# AT32F402xx_v2 register map
Vendor: Keil; Series: AT32F402; File version: 1.0
CPU: CM4 r0p1, little endian, no MPU, FPU, 4 interrupt priority bits
Registers are 32-bit, read-write, reset 0x0 unless marked. A register's access mark holds for its fields unless they carry their own. Offsets are from the block's base; [hi:lo] are bit positions; 'fields as' and 'values as' point back to an identical list.

## FLASH — Flash memory controler
Base 0x40023C00
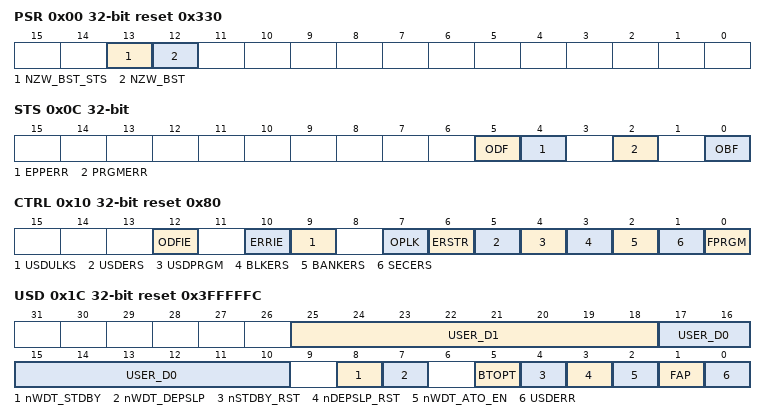
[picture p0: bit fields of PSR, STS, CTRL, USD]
0x00 PSR reset 0x330 — Performance selection register
  [13] NZW_BST_STS ro — Flash non-zero wait area boost status
  [12] NZW_BST — Flash non-zero wait area boost
0x04 UNLOCK wo
  [31:0] UKVAL — Unlock key value
0x08 USD_UNLOCK wo
  [31:0] USD_UKVAL — User system data Unlock key value
0x0C STS — Status register
  [5] ODF — Operate done flag
  [4] EPPERR — Erase/program protection error
  [2] PRGMERR — program error
  [0] OBF ro — Operate busy flag
0x10 CTRL reset 0x80 — Control register
  [12] ODFIE — Operation done flag interrupt enable
  [10] ERRIE — Error interrupt enable
  [9] USDULKS — User system data unlock success
  [7] OPLK — Operation lock
  [6] ERSTR — Erasing start
  [5] USDERS — User system data erase
  [4] USDPRGM — User system data program
  [3] BLKERS — Block erase
  [2] BANKERS — Bank erase
  [1] SECERS — Sector erase
  [0] FPRGM — Flash program
0x14 ADDR wo — Address register
  [31:0] FA — Flash Address
0x1C USD ro reset 0x3FFFFFC — User system data register
  [25:18] USER_D1 — User data 1
  [17:10] USER_D0 — User data 0
  [8] nWDT_STDBY — WDT standby
  [7] nWDT_DEPSLP — WDT deep sleep
  [5] BTOPT — boot option
  [4] nSTDBY_RST — Standby reset
  [3] nDEPSLP_RST — Deepsleep reset
  [2] nWDT_ATO_EN — WDT auto enable
  [1] FAP — FLASH access protection
  [0] USDERR — User system data error
0x20 EPPS0 ro reset 0xFFFFFFFF — Erase/program protection status register 0
  [31:0] EPPS — Erase/program protection status
0x2C EPPS1 ro reset 0xFFFFFFFF — Erase/program protection status register 1
  [31:0] EPPS — Erase/program protection status
0x44 UNLOCK2 wo
  [31:0] UKVAL — Unlock key value
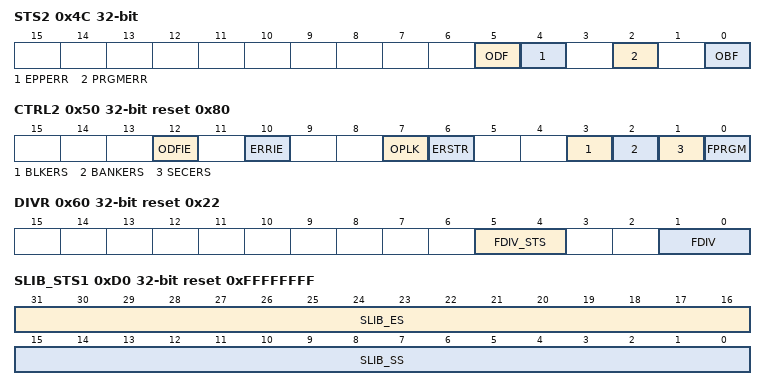
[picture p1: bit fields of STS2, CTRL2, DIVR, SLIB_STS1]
0x4C STS2 — Status 2 register
  fields as STS
0x50 CTRL2 reset 0x80 — Control 2 register
  [12] ODFIE — Operation done flag interrupt enable
  [10] ERRIE — Error interrupt enable
  [7] OPLK — Operation lock
  [6] ERSTR — Erasing start
  [3] BLKERS — Block erase
  [2] BANKERS — Bank erase
  [1] SECERS — Sector erase
  [0] FPRGM — Flash program
0x54 ADDR2 wo — Address 2 register
  [31:0] FA — Flash Address
0x58 CONTR reset 0x80 — Flash continue read register
  [31] FCONTR_EN — Flash continue read enable
0x60 DIVR reset 0x22 — Flash divider register
  [5:4] FDIV_STS ro — Flash divider status
  [1:0] FDIV — Flash divider
0xC8 SLIB_STS2 reset 0xFFFF — sLib status 2 register
  [15:0] SLIB_INST_SS ro — sLib instruction start sector
0xCC SLIB_STS0 — sLib status 0 register
  [3] SLIB_ENF ro — sLib enabled flag
0xD0 SLIB_STS1 reset 0xFFFFFFFF — sLib status 1 register
  [31:16] SLIB_ES ro — sLib end sector
  [15:0] SLIB_SS ro — sLib start sector
0xD4 SLIB_PWD_CLR wo — SLIB password clear register
  [31:0] SLIB_PCLR_VAL — sLib password clear value
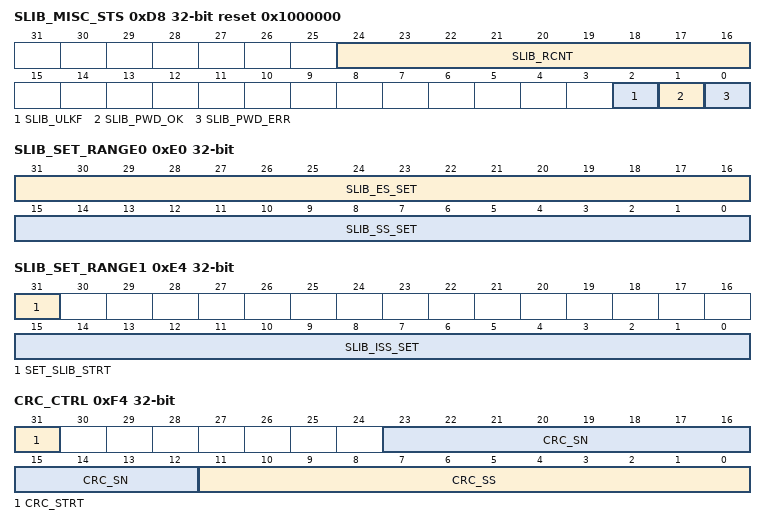
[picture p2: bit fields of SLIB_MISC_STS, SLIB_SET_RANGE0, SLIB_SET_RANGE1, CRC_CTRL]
0xD8 SLIB_MISC_STS reset 0x1000000 — sLib misc status register
  [24:16] SLIB_RCNT ro — sLib remaining count
  [2] SLIB_ULKF ro — sLib unlock flag
  [1] SLIB_PWD_OK ro — sLib password ok
  [0] SLIB_PWD_ERR ro — sLib password error
0xDC SLIB_SET_PWD wo — sLib password setting register
  [31:0] SLIB_PSET_VAL — sLib password setting val
0xE0 SLIB_SET_RANGE0 wo — Configure sLib range register 0
  [31:16] SLIB_ES_SET — sLib end sector setting
  [15:0] SLIB_SS_SET — sLib start sector setting
0xE4 SLIB_SET_RANGE1 wo — Configure sLib range register 1
  [31] SET_SLIB_STRT — sLib start setting
  [15:0] SLIB_ISS_SET — sLib instruction start sector setting
0xF0 SLIB_UNLOCK wo
  [31:0] SLIB_UKVAL — sLib unlock key value
0xF4 CRC_CTRL wo — CRC controler register
  [31] CRC_STRT — CRC start
  [23:12] CRC_SN — CRC sector numbler
  [11:0] CRC_SS — CRC start sector
0xF8 CRC_CHKR ro — CRC check result register
  [31:0] CRC_CHKR — CRC check result
